# DSS0_WB register map
Vendor: Texas Instruments
Peripheral module from a debugger description file (folder J7_AHP).
Registers are 32-bit, read-write, reset 0x0 unless marked. A register's access mark holds for its fields unless they carry their own. Offsets are as the file gives them; lines under a group give offsets from that group; [hi:lo] are bit positions; {n}, {i} and the like mark numbered series; 'fields as' and 'values as' point back to an identical list; <NAME> marks a mode.

## DSS0_WB
0x00 DISPC_0_WB_ACCUH_0
  [23:0] HORIZONTALACCU — Horizontal initialization accu signed value
0x04 DISPC_0_WB_ACCUH_1
  [23:0] HORIZONTALACCU — Horizontal initialization accu signed value
0x08 DISPC_0_WB_ACCUH2_0
  [23:0] HORIZONTALACCU — Horizontal initialization accu signed value
0x0C DISPC_0_WB_ACCUH2_1
  [23:0] HORIZONTALACCU — Horizontal initialization accu signed value
0x10 DISPC_0_WB_ACCUV_0
  [23:0] VERTICALACCU — Vertical initialization accu signed value
0x14 DISPC_0_WB_ACCUV_1
  [23:0] VERTICALACCU — Vertical initialization accu signed value
0x18 DISPC_0_WB_ACCUV2_0
  [23:0] VERTICALACCU — Vertical initialization accu signed value
0x1C DISPC_0_WB_ACCUV2_1
  [23:0] VERTICALACCU — Vertical initialization accu signed value
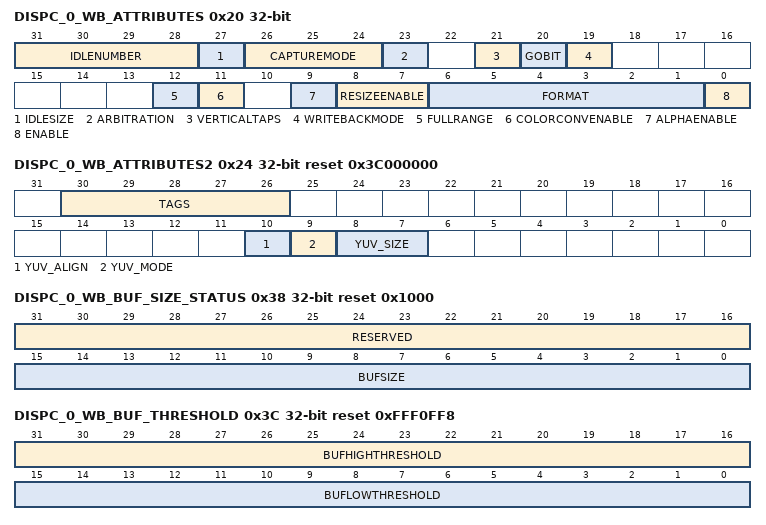
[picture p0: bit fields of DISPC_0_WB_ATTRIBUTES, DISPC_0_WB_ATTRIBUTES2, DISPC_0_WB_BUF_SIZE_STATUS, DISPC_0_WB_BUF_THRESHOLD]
0x20 DISPC_0_WB_ATTRIBUTES
  [31:28] IDLENUMBER — Determines the number of idles between requests on the L3 interconnect. It is only used when the write-back pipeline does data transfer from memory to memory. When the output of an overlay is stored in memory through the write-back pipeline in capture mode, the bit-field IDLENUMBER is ignored since a timing generator is used to time the transfer The number of IDLE cycles is IDLENUMBER [from 0 to 15] if IDLESIZE=0 The number of IDLE cycles is IDLENUMBERx8 [from 0 to 120] if IDLESIZE=1
  [27] IDLESIZE — Determines if the IDLENUMBER corresponds to a number of bursts or singles
  [26:24] CAPTUREMODE — Defines the frame rate capture
  [23] ARBITRATION — Determines the priority of the write-back pipeline. The write-back pipeline is one of the high priority pipelines. The arbitration gives always the priority first to the high priority pipelines using round-robin between them When there are only normal priority pipelines sending requests, the round-robin applies between them
  [21] VERTICALTAPS — Video Vertical Resize Tap Number
  [20] GOBIT — GO Command for the WB output. It is used to synchronize the pipelines associated with the WB output wr:immediate
  [19] WRITEBACKMODE — When connected to the overlay output of a channel the write back can operate as a simple transfer from memory to memory [composition engine] or as a capture channel
  [12] FULLRANGE — Color Space Conversion full range setting
  [11] COLORCONVENABLE — Enable the color space conversion. The HW does not enable/disable the conversion based on the pixel format. The bit-field shall be reset when the format is not YUV
  [9] ALPHAENABLE — Alpha enable on WB output
  [8:7] RESIZEENABLE
  [6:1] FORMAT — Write-back Format. It defines the pixel format when storing the write-back picture into memory
  [0] ENABLE — Write-back Enable wr: immediate
0x24 DISPC_0_WB_ATTRIBUTES2 reset 0x3C000000
  [30:26] TAGS — Number of OCP TAGS to be used for the pipeline [0x0 to 0xF]. A value of '0' means a single tag will be used. A value of 'F' means all 16 tags can be used
  [10] YUV_ALIGN — Alignment [MSB or LSB align] for unpacked 10b/12b YUV data
  [9] YUV_MODE — Mode of packing for YUV data [only for 10b/12b formats]
  [8:7] YUV_SIZE — Size of YUV data 8b/10b/12b
0x28 DISPC_0_WB_BA_0
  [31:0] BA — Write-back base address Base address of the WB buffer [aligned on pixel size boundary except in case of RGB24 packed format, where 4-pixel alignment is required. In case of YUV422, 2-pixel alignment is required, and YUV420, byte alignment is supported]] In case of YUV 4:2:0 format, it indicates the base address of the Y buffer
0x2C DISPC_0_WB_BA_1
  fields as DISPC_0_WB_BA_0
0x30 DISPC_0_WB_BA_UV_0
  [31:0] BA — WB base address aligned on 16-bit boundary. Base address of the UV WB buffer
0x34 DISPC_0_WB_BA_UV_1
  fields as DISPC_0_WB_BA_UV_0
0x38 DISPC_0_WB_BUF_SIZE_STATUS ro reset 0x1000
  [31:16] RESERVED — Write 0's for future compatibility. Reads return 0
  [15:0] BUFSIZE — DMA buffer Size in number of 128-bits
0x3C DISPC_0_WB_BUF_THRESHOLD reset 0xFFF0FF8
  [31:16] BUFHIGHTHRESHOLD — DMA buffer High Threshold Number of 128-bits defining the threshold value
  [15:0] BUFLOWTHRESHOLD — DMA buffer High Threshold Number of 128-bits defining the threshold value
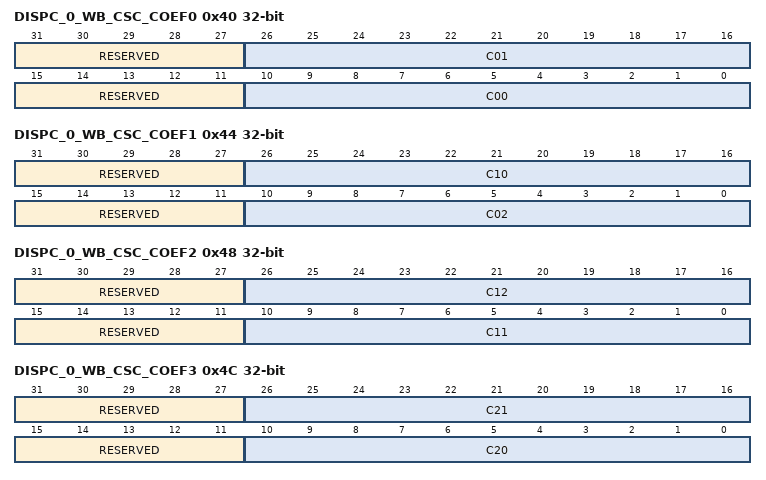
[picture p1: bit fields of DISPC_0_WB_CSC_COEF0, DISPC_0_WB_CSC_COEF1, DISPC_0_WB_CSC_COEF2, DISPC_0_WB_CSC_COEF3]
0x40 DISPC_0_WB_CSC_COEF0 access per field
  [31:27] RESERVED ro — Write 0's for future compatibility Reads return 0
  [26:16] C01 rw — C01 Coefficient. Encoded signed value [from -1024 to 1023]
  [15:11] RESERVED ro — Write 0's for future compatibility Reads return 0
  [10:0] C00 rw — C00 Coefficient. Encoded signed value [from -1024 to 1023]
0x44 DISPC_0_WB_CSC_COEF1 access per field
  [31:27] RESERVED ro — Write 0's for future compatibility Reads return 0
  [26:16] C10 rw — C10 Coefficient. Encoded signed value [from -1024 to 1023]
  [15:11] RESERVED ro — Write 0's for future compatibility Reads return 0
  [10:0] C02 rw — C02 Coefficient. Encoded signed value [from -1024 to 1023]
0x48 DISPC_0_WB_CSC_COEF2 access per field
  [31:27] RESERVED ro — Write 0's for future compatibility Reads return 0
  [26:16] C12 rw — C12 Coefficient. Encoded signed value [from -1024 to 1023]
  [15:11] RESERVED ro — Write 0's for future compatibility Reads return 0
  [10:0] C11 rw — C11 Coefficient. Encoded signed value [from -1024 to 1023]
0x4C DISPC_0_WB_CSC_COEF3 access per field
  [31:27] RESERVED ro — Write 0's for future compatibility Reads return 0
  [26:16] C21 rw — C21 coefficient. Encoded signed value [from -1024 to 1023]
  [15:11] RESERVED ro — Write 0's for future compatibility Reads return 0
  [10:0] C20 rw — C20 coefficient. Encoded signed value [from -1024 to 1023]
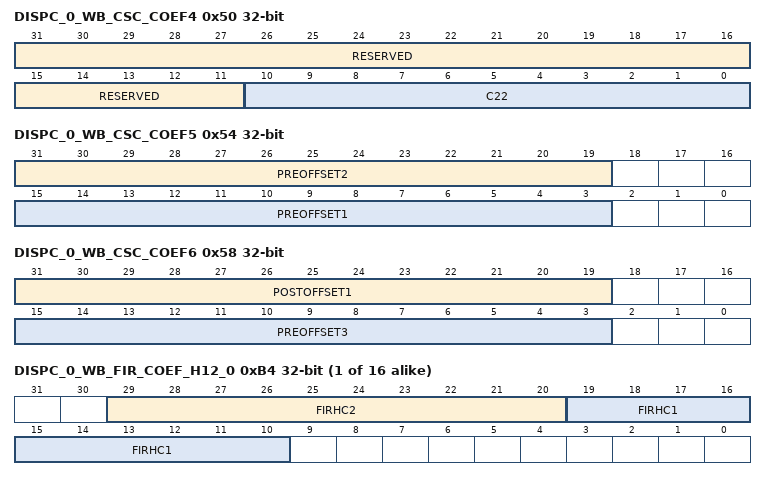
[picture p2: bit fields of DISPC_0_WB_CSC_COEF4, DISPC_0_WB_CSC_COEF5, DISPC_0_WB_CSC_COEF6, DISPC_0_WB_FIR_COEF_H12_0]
0x50 DISPC_0_WB_CSC_COEF4 access per field
  [31:11] RESERVED ro — Write 0's for future compatibility Reads return 0
  [10:0] C22 rw — C22 Coefficient. Encoded signed value [from -1024 to 1023]
0x54 DISPC_0_WB_CSC_COEF5
  [31:19] PREOFFSET2 — Row-2 pre-offset. Encoded signed value [from -4096 to 4095]
  [15:3] PREOFFSET1 — Row1 pre-offset. Encoded signed value [from -4096 to 4095]
0x58 DISPC_0_WB_CSC_COEF6
  [31:19] POSTOFFSET1 — Row-1 post-offset. Encoded signed value [from -4096 to 4095]
  [15:3] PREOFFSET3 — Row-3 pre-offset. Encoded signed value [from -4096 to 4095]
0x5C DISPC_0_WB_FIRH reset 0x200000
  [23:0] FIRHINC — Horizontal increment of the up/down-sampling filter. The value 0 is invalid
0x60 DISPC_0_WB_FIRH2 reset 0x200000
  [23:0] FIRHINC — Horizontal increment of the up/down-sampling filter for Cb and Cr. The value 0 is invalid
0x64 DISPC_0_WB_FIRV reset 0x200000
  [23:0] FIRVINC — Vertical increment of the up/down-sampling filter. The value 0 is invalid
0x68 DISPC_0_WB_FIRV2 reset 0x200000
  [23:0] FIRVINC — Vertical increment of the up/down-sampling filter for Cb and Cr. The value 0 is invalid
{0x6C+4i} DISPC_0_WB_FIR_COEF_H0_{i} (i=0..8)
  [9:0] FIRHC0 — Unsigned coefficient C0 for the horizontal up/down-scaling with the phase n
{0x90+4i} DISPC_0_WB_FIR_COEF_H0_C_{i} (i=0..8)
  fields as DISPC_0_WB_FIR_COEF_H0_0
{0xB4+4i} DISPC_0_WB_FIR_COEF_H12_{i} (i=0..15)
  [29:20] FIRHC2 — Signed coefficient C2 for the horizontal up/down-scaling with the phase n
  [19:10] FIRHC1 — Signed coefficient C1 for the horizontal up/down-scaling with the phase n
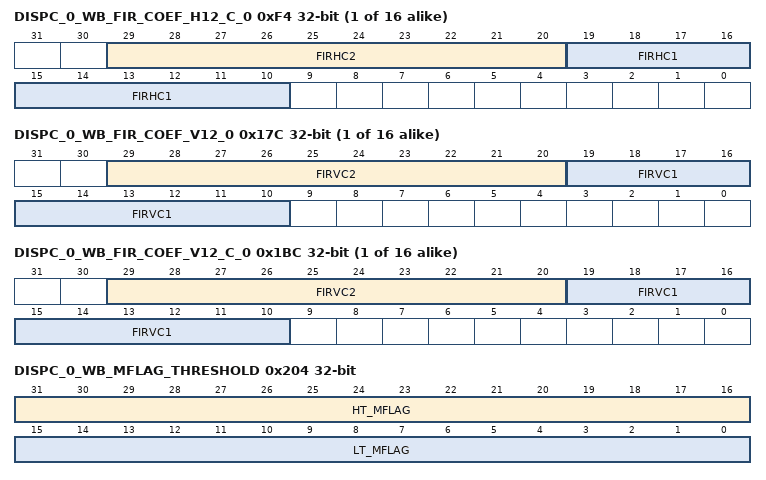
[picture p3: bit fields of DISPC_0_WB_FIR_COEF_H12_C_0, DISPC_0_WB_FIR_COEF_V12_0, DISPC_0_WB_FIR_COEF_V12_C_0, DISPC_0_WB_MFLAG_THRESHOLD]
{0xF4+4i} DISPC_0_WB_FIR_COEF_H12_C_{i} (i=0..15)
  fields as DISPC_0_WB_FIR_COEF_H12_0
{0x134+4i} DISPC_0_WB_FIR_COEF_V0_{i} (i=0..8)
  [9:0] FIRVC0 — Unsigned coefficient C0 for the vertical up/down-scaling with the phase n
{0x158+4i} DISPC_0_WB_FIR_COEF_V0_C_{i} (i=0..8)
  fields as DISPC_0_WB_FIR_COEF_V0_0
{0x17C+4i} DISPC_0_WB_FIR_COEF_V12_{i} (i=0..15)
  [29:20] FIRVC2 — Signed coefficient C2 for the vertical up/down-scaling with the phase n
  [19:10] FIRVC1 — Signed coefficient C1 for the vertical up/down-scaling with the phase n
{0x1BC+4i} DISPC_0_WB_FIR_COEF_V12_C_{i} (i=0..15)
  fields as DISPC_0_WB_FIR_COEF_V12_0
0x204 DISPC_0_WB_MFLAG_THRESHOLD
  [31:16] HT_MFLAG — MFlag High Threshold
  [15:0] LT_MFLAG — MFlag Low Threshold
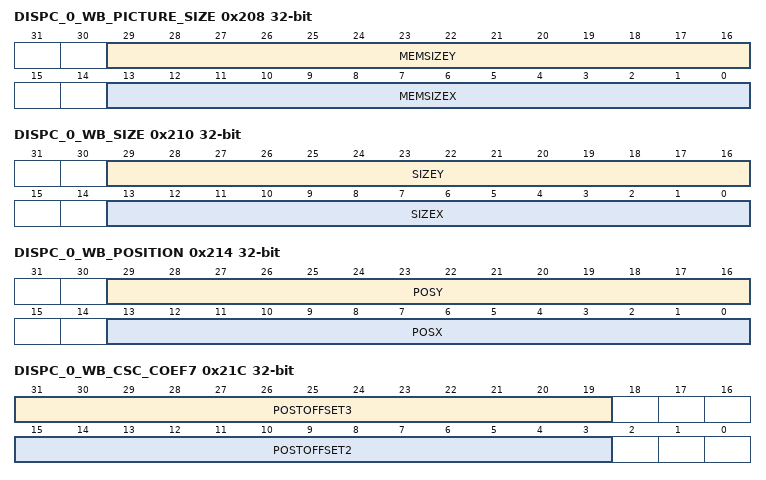
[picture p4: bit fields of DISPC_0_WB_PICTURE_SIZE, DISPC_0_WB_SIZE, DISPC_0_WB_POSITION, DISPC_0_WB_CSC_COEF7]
0x208 DISPC_0_WB_PICTURE_SIZE
  [29:16] MEMSIZEY — Number of lines of the wb picture in memory Encoded value [from 1 to 16384] to specify the number of lines of the picture store in memory [program to value minus one]
  [13:0] MEMSIZEX — Number of pixels of the wb picture in memory Encoded value [from 1 to 16384] to specify the number of pixels of the picture stored in memory [program to value minus one]
0x210 DISPC_0_WB_SIZE
  [29:16] SIZEY — Number of lines of the Write-back picture Encoded value [from 1 to 16384] to specify the number of lines of the write-back picture from overlay or pipeline
  [13:0] SIZEX — Number of pixels of the Write-back picture Encoded value [from 1 to 16384] to specify the number of pixels of the write-back picture from overlay or pipeline
0x214 DISPC_0_WB_POSITION
  [29:16] POSY — Y position of the video window Encoded value [from 0 to 16384] to specify the Y position of the video window 1 The line at the top has the Y-position 0
  [13:0] POSX — X position of the video window Encoded value [from 0 to 16384] to specify the X position of the video window 1 The first pixel on the left of the display screen has the X-position 0
0x21C DISPC_0_WB_CSC_COEF7
  [31:19] POSTOFFSET3 — Row-3 post-offset. Encoded signed value [from -4096 to 4095]
  [15:3] POSTOFFSET2 — Row-2 post-offset. Encoded signed value [from -4096 to 4095]
0x224 DISPC_0_WB_ROW_INC reset 0x1
  [31:0] ROWINC — Number of bytes to increment at the end of the row Encoded signed value [from -2^31-1 to 2^31] to specify the number of bytes to increment at the end of the row in the video buffer The value 0 is invalid The value 1 means next pixel The value 1+n*bpp means increment of n pixels The value 1- [n+1]*bpp means decrement of n pixels
0x228 DISPC_0_WB_ROW_INC_UV reset 0x1
  fields as DISPC_0_WB_ROW_INC
0x22C DISPC_0_WB_BA_EXT_0
  [15:0] BA_EXT — Video base address extension [16 bits]. Addr extension to make the address space 48b wide
0x230 DISPC_0_WB_BA_EXT_1
  fields as DISPC_0_WB_BA_EXT_0
0x234 DISPC_0_WB_BA_UV_EXT_0
  [15:0] BA_UV_EXT — Video base address extension [16 bits]. Addr extension to make the address space 48b wide
0x238 DISPC_0_WB_BA_UV_EXT_1
  fields as DISPC_0_WB_BA_UV_EXT_0
0x248 DISPC_0_WB_SECURE
  [0] SECURE — Secure bit
